# CY8C5488AXI_LP120 register map
File version: 0.1
Registers are 8-bit, read-write, no defined reset value unless marked. A register's access mark holds for its fields unless they carry their own. Offsets are from the block's base; [hi:lo] are bit positions; 'fields as' and 'values as' point back to an identical list.

## Arm_PWM
Base 0x00000000
0x40006422 Arm_PWM_COMPARE_Reg 16-bit — UDB.D0 - Assigned Compare Value
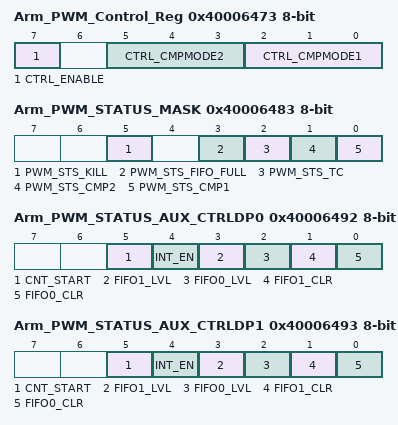
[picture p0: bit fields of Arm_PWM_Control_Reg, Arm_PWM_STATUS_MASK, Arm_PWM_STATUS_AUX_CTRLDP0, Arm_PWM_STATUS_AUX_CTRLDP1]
0x40006473 Arm_PWM_Control_Reg — UDB Control Register - Assigned Control Register Value
  [7] CTRL_ENABLE — Enable the PWM
  [5:3] CTRL_CMPMODE2 — Compare mode 2
  [2:0] CTRL_CMPMODE1 — Compare mode 1
0x40006483 Arm_PWM_STATUS_MASK — UDB Status bits Interrupt Mask Enable Register
  [5] PWM_STS_KILL ro — Enables the Interrupt on Kill
  [3] PWM_STS_FIFO_FULL ro — FIFO Full Status Mask
  [2] PWM_STS_TC ro — Enables the Interrupt on Terminal Count
  [1] PWM_STS_CMP2 ro — Enables the Interrupt on Compare 2
  [0] PWM_STS_CMP1 ro — Enables the Interrupt on Compare 1
0x40006492 Arm_PWM_STATUS_AUX_CTRLDP0 — UDB Auxilliary Control Register
  [5] CNT_START — FIFO0 clear
    0=E_CNT_START0 (Disable counter); 1=E_CNT_START1 (Enable counter)
  [4] INT_EN
    0=E_INT_EN0 (Interrupt disabled); 1=E_INT_EN1 (Interrupt enabled)
  [3] FIFO1_LVL — FIFO level
    0=E_FIFO_LVL_0 (FIFO LVL: input mode: FIFO not full; output mode: FIFO not empty); 1=E_FIFO_LVL_1 (FIFO LVL: input mode: FIFO at least 1/2 empty; output mode: FIFO at least 1/2 full)
  [2] FIFO0_LVL — FIFO level
    values as FIFO1_LVL
  [1] FIFO1_CLR — FIFO1 clear
    0=E_FIFO_CLR_0 (Normal FIFO operation); 1=E_FIFO_CLR_1 (Clear FIFO state)
  [0] FIFO0_CLR — FIFO0 clear
    values as FIFO1_CLR
0x40006493 Arm_PWM_STATUS_AUX_CTRLDP1 — UDB Auxilliary Control Register
  fields as Arm_PWM_STATUS_AUX_CTRLDP0

## HC_Timer
Base 0x00000000
0x40006504 HC_Timer_COUNTER 16-bit — UDB.A0 - Current Down Counter Value
0x40006524 HC_Timer_PERIOD 16-bit — UDB.D0 - Assigned Period
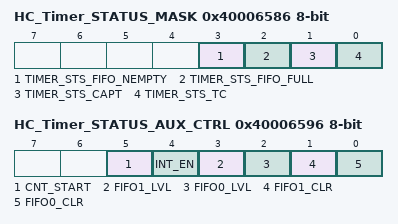
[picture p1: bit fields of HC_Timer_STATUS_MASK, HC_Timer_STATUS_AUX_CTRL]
0x40006586 HC_Timer_STATUS_MASK — UDB Status bits Interrupt Mask Enable Register
  [3] TIMER_STS_FIFO_NEMPTY ro — FIFO Empty status
  [2] TIMER_STS_FIFO_FULL ro — FIFO Full Status
  [1] TIMER_STS_CAPT ro — Enables the Interrupt on Capture
  [0] TIMER_STS_TC ro — Enables the Interrupt on TC
0x40006596 HC_Timer_STATUS_AUX_CTRL — UDB Auxilliary Control Register
  [5] CNT_START — FIFO0 clear
    0=E_CNT_START0 (Disable counter); 1=E_CNT_START1 (Enable counter)
  [4] INT_EN
    0=E_INT_EN0 (Interrupt disabled); 1=E_INT_EN1 (Interrupt enabled)
  [3] FIFO1_LVL — FIFO level
    0=E_FIFO_LVL_0 (FIFO LVL: input mode: FIFO not full; output mode: FIFO not empty); 1=E_FIFO_LVL_1 (FIFO LVL: input mode: FIFO at least 1/2 empty; output mode: FIFO at least 1/2 full)
  [2] FIFO0_LVL — FIFO level
    values as FIFO1_LVL
  [1] FIFO1_CLR — FIFO1 clear
    0=E_FIFO_CLR_0 (Normal FIFO operation); 1=E_FIFO_CLR_1 (Clear FIFO state)
  [0] FIFO0_CLR — FIFO0 clear
    values as FIFO1_CLR

## HC_PWM
Base 0x00000000
0x40006526 HC_PWM_COMPARE_1 16-bit — UDB.D0 - Assigned Compare1 Value
0x40006536 HC_PWM_COMPARE_2 16-bit — UDB.D1 - Assigned Compare2 Value
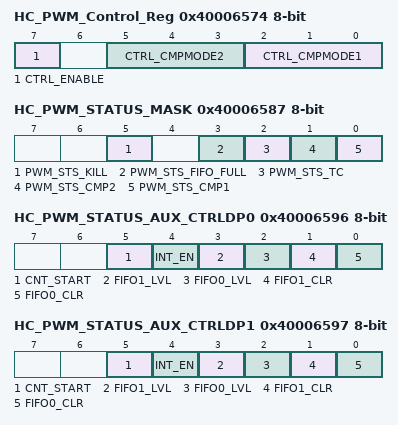
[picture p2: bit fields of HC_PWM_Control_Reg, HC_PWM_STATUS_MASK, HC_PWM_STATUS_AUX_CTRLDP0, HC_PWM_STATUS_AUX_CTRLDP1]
0x40006574 HC_PWM_Control_Reg — UDB Control Register - Assigned Control Register Value
  [7] CTRL_ENABLE — Enable the PWM
  [5:3] CTRL_CMPMODE2 — Compare mode 2
  [2:0] CTRL_CMPMODE1 — Compare mode 1
0x40006587 HC_PWM_STATUS_MASK — UDB Status bits Interrupt Mask Enable Register
  [5] PWM_STS_KILL ro — Enables the Interrupt on Kill
  [3] PWM_STS_FIFO_FULL ro — FIFO Full Status Mask
  [2] PWM_STS_TC ro — Enables the Interrupt on Terminal Count
  [1] PWM_STS_CMP2 ro — Enables the Interrupt on Compare 2
  [0] PWM_STS_CMP1 ro — Enables the Interrupt on Compare 1
0x40006596 HC_PWM_STATUS_AUX_CTRLDP0 — UDB Auxilliary Control Register
  [5] CNT_START — FIFO0 clear
    0=E_CNT_START0 (Disable counter); 1=E_CNT_START1 (Enable counter)
  [4] INT_EN
    0=E_INT_EN0 (Interrupt disabled); 1=E_INT_EN1 (Interrupt enabled)
  [3] FIFO1_LVL — FIFO level
    0=E_FIFO_LVL_0 (FIFO LVL: input mode: FIFO not full; output mode: FIFO not empty); 1=E_FIFO_LVL_1 (FIFO LVL: input mode: FIFO at least 1/2 empty; output mode: FIFO at least 1/2 full)
  [2] FIFO0_LVL — FIFO level
    values as FIFO1_LVL
  [1] FIFO1_CLR — FIFO1 clear
    0=E_FIFO_CLR_0 (Normal FIFO operation); 1=E_FIFO_CLR_1 (Clear FIFO state)
  [0] FIFO0_CLR — FIFO0 clear
    values as FIFO1_CLR
0x40006597 HC_PWM_STATUS_AUX_CTRLDP1 — UDB Auxilliary Control Register
  fields as HC_PWM_STATUS_AUX_CTRLDP0
